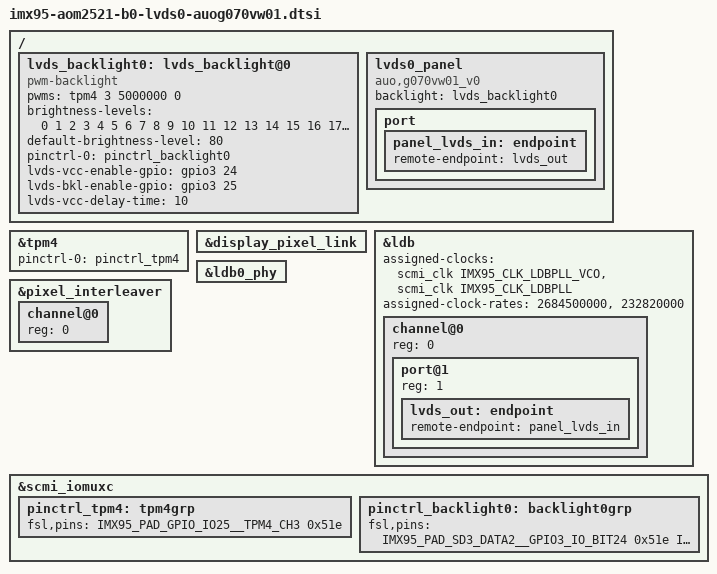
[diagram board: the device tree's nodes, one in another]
/ {
	lvds_backlight0: lvds_backlight@0 {
		compatible = "pwm-backlight";
		pwms = <&tpm4 3 5000000 0>;
		status = "disabled";

		brightness-levels = < 0  1  2  3  4  5  6  7  8  9
				     10 11 12 13 14 15 16 17 18 19
				     20 21 22 23 24 25 26 27 28 29
				     30 31 32 33 34 35 36 37 38 39
				     40 41 42 43 44 45 46 47 48 49
				     50 51 52 53 54 55 56 57 58 59
				     60 61 62 63 64 65 66 67 68 69
				     70 71 72 73 74 75 76 77 78 79
				     80 81 82 83 84 85 86 87 88 89
				     90 91 92 93 94 95 96 97 98 99
				    100>;
		default-brightness-level = <80>;
	};

	lvds0_panel {
		compatible = "auo,g070vw01_v0";
		backlight = <&lvds_backlight0>;

		port {
			panel_lvds_in: endpoint {
				remote-endpoint = <&lvds_out>;
			};
		};
	};
};

&tpm4 {
	pinctrl-names = "default";
	pinctrl-0 = <&pinctrl_tpm4>;
	status = "okay";
};

&display_pixel_link {
	status = "okay";
};

&ldb {
	#address-cells = <1>;
	#size-cells = <0>;
	assigned-clocks = <&scmi_clk IMX95_CLK_LDBPLL_VCO>,
			  <&scmi_clk IMX95_CLK_LDBPLL>;
	assigned-clock-rates = <2684500000>, <232820000>;
	status = "okay";

	channel@0 {
		#address-cells = <1>;
		#size-cells = <0>;
		status = "okay";
		reg = <0>;

		port@1 {
			reg = <1>;

			lvds_out: endpoint {
				remote-endpoint = <&panel_lvds_in>;
			};
		};
	};
};

&ldb0_phy {
	status = "okay";
};

&lvds_backlight0 {
	pinctrl-names = "default";
	pinctrl-0 = <&pinctrl_backlight0>;
	lvds-vcc-enable-gpio = <&gpio3 24 GPIO_ACTIVE_HIGH>;	/* LVDS_VDD_EN */
	lvds-bkl-enable-gpio = <&gpio3 25 GPIO_ACTIVE_HIGH>;	/* LVDS_BL_EN */
	lvds-vcc-delay-time = <10>;
	status = "okay";
};

&pixel_interleaver {
	#address-cells = <1>;
	#size-cells = <0>;
	status = "okay";

	channel@0 {
		reg = <0>;
		status = "okay";
	};
};

&scmi_iomuxc {
	pinctrl_tpm4: tpm4grp {
		fsl,pins = <
			IMX95_PAD_GPIO_IO25__TPM4_CH3		0x51e	/* LVDS_BL_PWM */
		>;
	};

	pinctrl_backlight0: backlight0grp {
		fsl,pins = <
			IMX95_PAD_SD3_DATA2__GPIO3_IO_BIT24	0x51e  /* LVDS_VDD_EN */
			IMX95_PAD_SD3_DATA3__GPIO3_IO_BIT25     0x51e  /* LVDS_BL_EN  */
		>;
	};
};
